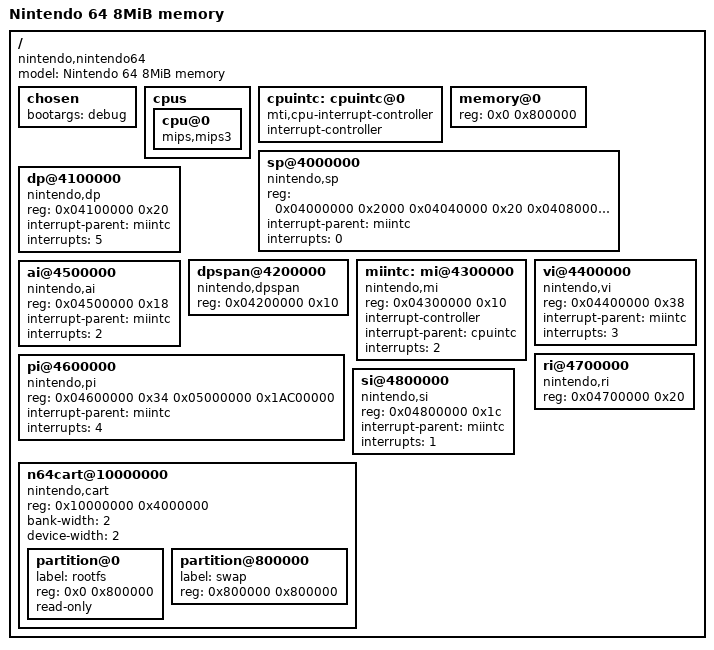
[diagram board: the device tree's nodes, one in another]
/dts-v1/;

/* note: N64 external bus is 32bit, so #address-cells=<1> on 64bit too is ok. */

/ {
	#address-cells = <1>;
	#size-cells = <1>;
	compatible = "nintendo,nintendo64";
	model = "Nintendo 64 8MiB memory";

	chosen {
		bootargs = "debug";
	};

	cpus {
		cpu@0 {
			compatible = "mips,mips3";
		};
	};

	cpuintc: cpuintc@0 {
		compatible = "mti,cpu-interrupt-controller";
		//#address-cells = <0>;

		interrupt-controller;
		#interrupt-cells = <1>;
		// from mupen64plus:
		// IM/IP2: MI_INTR
		// IM/IP4: HW2? (reset button; PreNMI)
		// IM/IP7: Compare (also noted in 007-2489-001.pdf pp.104(134/754 pdf pages))
	};

	memory@0 {
		device_type = "memory";
		reg = <0x0 0x800000>;
	};

	sp@4000000 {
		compatible = "nintendo,sp";
		reg = <0x04000000 0x2000 0x04040000 0x20 0x04080000 0x8>;

		interrupt-parent = <&miintc>;
		interrupts = <0>;
	};

	dp@4100000 {
		compatible = "nintendo,dp";
		reg = <0x04100000 0x20>;

		interrupt-parent = <&miintc>;
		interrupts = <5>;
	};

	dpspan@4200000 {
		compatible = "nintendo,dpspan";
		reg = <0x04200000 0x10>;
	};

	miintc: mi@4300000 {
		compatible = "nintendo,mi";
		reg = <0x04300000 0x10>;

		interrupt-controller;
		#interrupt-cells = <1>;

		interrupt-parent = <&cpuintc>;
		interrupts = <2>;
	};

	vi@4400000 {
		compatible = "nintendo,vi";
		reg = <0x04400000 0x38>;

		interrupt-parent = <&miintc>;
		interrupts = <3>;
	};

	ai@4500000 {
		compatible = "nintendo,ai";
		reg = <0x04500000 0x18>;

		interrupt-parent = <&miintc>;
		interrupts = <2>;
	};

	pi@4600000 {
		compatible = "nintendo,pi";
		reg = <0x04600000 0x34 0x05000000 0x1AC00000>;

		interrupt-parent = <&miintc>;
		interrupts = <4>;
	};

	ri@4700000 {
		compatible = "nintendo,ri";
		reg = <0x04700000 0x20>;
	};

	si@4800000 {
		compatible = "nintendo,si";
		reg = <0x04800000 0x1c>;

		interrupt-parent = <&miintc>;
		interrupts = <1>;
	};

	// dummy
	n64cart@10000000 {
		compatible = "nintendo,cart";
		reg = <0x10000000 0x4000000>;

		bank-width = <2>;
		device-width = <2>;
		#address-cells = <1>;
		#size-cells = <1>;

		partition@0 {
			label = "ipl3";
			reg = <0x0 0x1040>;
			read-only;
		};
		partition@0 {
			label = "rootfs";
			reg = <0x0 0x800000>;
			read-only;
		};
		partition@800000 {
			label = "swap";
			reg = <0x800000 0x800000>;
		};
	};
};
